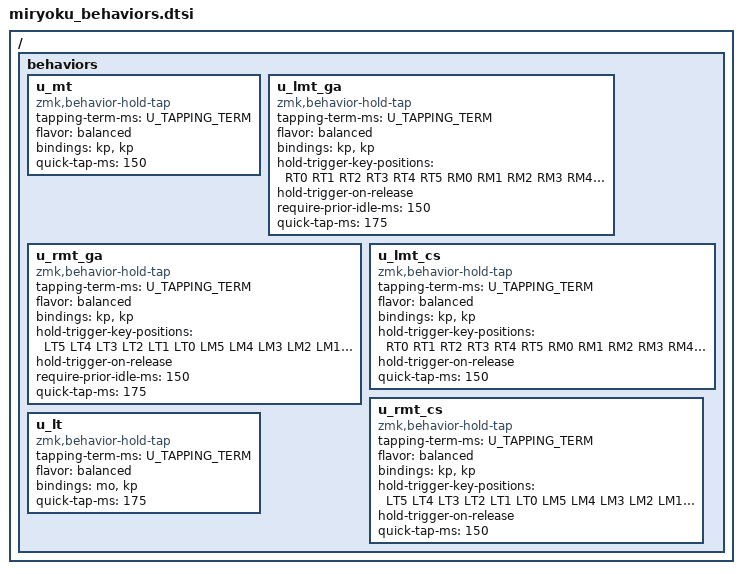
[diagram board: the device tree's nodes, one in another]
// Copyright 2022 Manna Harbour
// https://github.com/manna-harbour/miryoku

#include "zmk-helpers/key-labels/42.h"

/ {
  behaviors {
    u_mt: u_mt {
      compatible = "zmk,behavior-hold-tap";
      #binding-cells = <2>;
      tapping-term-ms = <U_TAPPING_TERM>;
      flavor = "balanced";
      bindings = <&kp>, <&kp>;
      quick-tap-ms = <150>;
    };
    u_lmt_ga: u_lmt_ga {
      compatible = "zmk,behavior-hold-tap";
      #binding-cells = <2>;
      tapping-term-ms = <U_TAPPING_TERM>;
      flavor = "balanced";
      bindings = <&kp>, <&kp>;
      hold-trigger-key-positions = <RT0 RT1 RT2 RT3 RT4 RT5   RM0 RM1 RM2 RM3 RM4 RM5   RB0 RB1 RB2 RB3 RB4 RB5   LH2 LH1 LH0 RH0 RH1 RH2>;
      hold-trigger-on-release;
      require-prior-idle-ms = <150>;
      quick-tap-ms = <175>;
    };
    u_rmt_ga: u_rmt_ga {
      compatible = "zmk,behavior-hold-tap";
      #binding-cells = <2>;
      tapping-term-ms = <U_TAPPING_TERM>;
      flavor = "balanced";
      bindings = <&kp>, <&kp>;
      hold-trigger-key-positions = <LT5 LT4 LT3 LT2 LT1 LT0   LM5 LM4 LM3 LM2 LM1 LM0   LB5 LB4 LB3 LB2 LB1 LB0   LH2 LH1 LH0 RH0 RH1 RH2>;
      hold-trigger-on-release;
      require-prior-idle-ms = <150>;
      quick-tap-ms = <175>;
    };
    u_lmt_cs: u_lmt_cs {
      compatible = "zmk,behavior-hold-tap";
      #binding-cells = <2>;
      tapping-term-ms = <U_TAPPING_TERM>;
      flavor = "balanced";
      bindings = <&kp>, <&kp>;
      hold-trigger-key-positions = <RT0 RT1 RT2 RT3 RT4 RT5   RM0 RM1 RM2 RM3 RM4 RM5   RB0 RB1 RB2 RB3 RB4 RB5   LH2 LH1 LH0 RH0 RH1 RH2>;
      hold-trigger-on-release;
      quick-tap-ms = <150>;
    };
    u_rmt_cs: u_rmt_cs {
      compatible = "zmk,behavior-hold-tap";
      #binding-cells = <2>;
      tapping-term-ms = <U_TAPPING_TERM>;
      flavor = "balanced";
      bindings = <&kp>, <&kp>;
      hold-trigger-key-positions = <LT5 LT4 LT3 LT2 LT1 LT0   LM5 LM4 LM3 LM2 LM1 LM0   LB5 LB4 LB3 LB2 LB1 LB0   LH2 LH1 LH0 RH0 RH1 RH2>;
      hold-trigger-on-release;
      quick-tap-ms = <150>;
    };
    u_lt: u_lt {
      compatible = "zmk,behavior-hold-tap";
      #binding-cells = <2>;
      tapping-term-ms = <U_TAPPING_TERM>;
      flavor = "balanced";
      bindings = <&mo>, <&kp>;
      quick-tap-ms = <175>;
    };
  };
};
